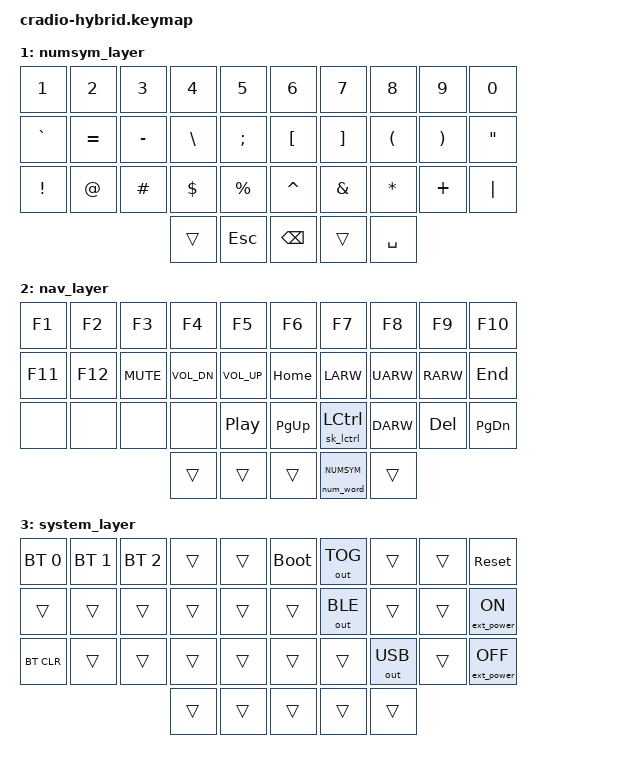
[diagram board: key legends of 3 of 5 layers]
// Copyright (c) 2022 The ZMK Contributors
// SPDX-License-Identifier: MIT
//
// OPTION 4: HYBRID PROGRESSIVE APPROACH
// - Dual-mode layer access (both hold AND toggle available)
// - Gradual transition features with fallback options
// - Selective HRM with optional full HRM mode
// - Experimental features for power users
// - Safe experimentation without losing productivity

#include <behaviors/num_word.dtsi>
#include <behaviors.dtsi>
#include <dt-bindings/zmk/keys.h>
#include <dt-bindings/zmk/bt.h>
#include <dt-bindings/zmk/outputs.h>
#include <dt-bindings/zmk/ext_power.h>

// ---------- Layer indexes ----------
#define BASE     0 
#define NUMSYM   1
#define NAV      2
#define SYSTEM   3
#define ALT_BASE 4  // Alternative base layer with different HRM

// ---------- Full Home-row Mods (original style) ----------
#define HRML_FULL(k1,k2,k3,k4) &ht LSHFT k1  &ht LALT k2   &ht LCTRL k3   &ht LGUI k4
#define HRMR_FULL(k1,k2,k3,k4) &ht RGUI k1   &ht RCTRL k2  &ht RALT k3    &ht RSHFT k4

// ---------- Selective Home-row Mods (experimental) ----------
#define HRML_LITE(k1,k2,k3,k4) &kp k1  &ht_slow LALT k2   &kp k3   &ht_slow LGUI k4
#define HRMR_LITE(k1,k2,k3,k4) &ht_slow RGUI k1   &kp k2  &ht_slow RALT k3    &kp k4

/ {
    behaviors {
        // Original hold-tap for familiar feel
        ht: hold_tap {
            compatible = "zmk,behavior-hold-tap";
            #binding-cells = <2>;
            flavor = "tap-preferred";
            tapping-term-ms = <200>;
            quick-tap-ms = <120>;
            require-prior-idle-ms = <100>;
            bindings = <&kp>, <&kp>;
        };

        // Slower hold-tap for selective HRM
        ht_slow: hold_tap_slow {
            compatible = "zmk,behavior-hold-tap";
            #binding-cells = <2>;
            flavor = "tap-preferred";
            tapping-term-ms = <280>;
            quick-tap-ms = <100>;
            require-prior-idle-ms = <150>;
            bindings = <&kp>, <&kp>;
        };

        // Dual-mode layer access - hold for momentary, tap for toggle
        dual_layer: dual_layer_access {
            compatible = "zmk,behavior-tap-dance";
            #binding-cells = <1>;
            tapping-term-ms = <200>;
            bindings = <&lt_hold>, <&to>;
        };

        // Hold for momentary layer
        lt_hold: layer_tap_hold {
            compatible = "zmk,behavior-hold-tap";
            #binding-cells = <2>;
            flavor = "tap-preferred";
            tapping-term-ms = <200>;
            quick-tap-ms = <120>;
            require-prior-idle-ms = <100>;
            bindings = <&mo>, <&kp>;
        };

        // Sticky modifiers
        sk_lshft: sticky_shift {
            compatible = "zmk,behavior-sticky-key";
            #binding-cells = <1>;
            bindings = <&kp>;
            release-after-ms = <1000>;
            quick-release;
        };

        sk_lctrl: sticky_ctrl {
            compatible = "zmk,behavior-sticky-key";
            #binding-cells = <1>;
            bindings = <&kp>;
            release-after-ms = <1000>;
            quick-release;
        };

        // Experimental multi-function thumb
        mt_experimental: mod_tap_experimental {
            compatible = "zmk,behavior-tap-dance";
            #binding-cells = <0>;
            tapping-term-ms = <200>;
            bindings = <&kp SPACE>, <&sk_lshft LSHFT>, <&to ALT_BASE>;
        };
    };

    // ---------- Combos for advanced functionality ----------
    combos {
        compatible = "zmk,combos";
        
        // Panic mode - always available
        combo_panic {
            timeout-ms = <50>;
            key-positions = <30 33>;
            bindings = <&to BASE>;
            layers = <BASE NUMSYM NAV SYSTEM ALT_BASE>;
        };

        // Essential shortcuts
        combo_enter {
            timeout-ms = <40>;
            key-positions = <17 18 19>; // J K L
            bindings = <&kp ENTER>;
            layers = <BASE ALT_BASE>;
        };

        combo_hyphen {
            timeout-ms = <40>;
            key-positions = <22 23>; // C V
            bindings = <&kp MINUS>;
            layers = <BASE ALT_BASE>;
        };

        combo_tab {
            timeout-ms = <40>;
            key-positions = <12 13>; // D F
            bindings = <&kp TAB>;
            layers = <BASE ALT_BASE>;
        };

        // Quick layer switches
        combo_toggle_nav {
            timeout-ms = <50>;
            key-positions = <14 15>; // T G
            bindings = <&tog NAV>;
            layers = <BASE>;
        };

        combo_toggle_numsym {
            timeout-ms = <50>;
            key-positions = <15 16>; // G H
            bindings = <&tog NUMSYM>;
            layers = <BASE>;
        };

        // Switch between HRM modes
        combo_switch_hrm {
            timeout-ms = <100>;
            key-positions = <0 1 8 9>; // Q W O P
            bindings = <&tog ALT_BASE>;
            layers = <BASE ALT_BASE>;
        };
    };

    // ---------- Conditional tri-layer ----------
    conditional_layers {
        compatible = "zmk,conditional-layers";
        system_layer {
            if-layers = <NAV NUMSYM>;
            then-layer = <SYSTEM>;
        };
    };

    keymap {
        compatible = "zmk,keymap";
        
        // Original style base layer with full HRM
        base_layer {
            bindings = <
        //╭──────────┬──────────┬──────────┬──────────┬──────────╮   ╭──────────┬──────────┬──────────┬──────────┬──────────╮
        //│  Q       │  W       │  E       │  R       │  T       │   │  Y       │  U       │  I       │  O       │  P       │
             &kp Q      &kp W      &kp E      &kp R      &kp T          &kp Y      &kp U      &kp I      &kp O      &kp P
        //├──────────┼──────────┼──────────┼──────────┼──────────┤   ├──────────┼──────────┼──────────┼──────────┼──────────┤
        //│  A       │  S       │  D       │  F       │  G       │   │  H       │  J       │  K       │  L       │ ' "      │
             HRML_FULL(A, S,       D,         F)         &kp G          &kp H      HRMR_FULL(J, K,       L,        SQT)
        //├──────────┼──────────┼──────────┼──────────┼──────────┤   ├──────────┼──────────┼──────────┼──────────┼──────────┤
        //│  Z       │  X       │  C       │  V       │  B       │   │  N       │  M       │ , <      │ . >      │ / ?      │
            &kp Z      &kp X      &kp C      &kp V      &kp B          &kp N      &kp M      &kp COMMA  &kp DOT    &kp FSLH
        //╰──────────┴──────────┴──────────┼──────────┼──────────┤   ├──────────┼──────────┼──────────┴──────────┴──────────╯
                                 &dual_layer NAV &lt_hold NAV TAB    &kp ENTER  &lt_hold NUMSYM BSPC &mt_experimental
        //                                 ╰──────────┴──────────╯   ╰──────────┴──────────╯
            >;
        };

        numsym_layer {
            bindings = <
        //╭──────────┬──────────┬──────────┬──────────┬──────────╮   ╭──────────┬──────────┬──────────┬──────────┬──────────╮
        //│ 1        │ 2        │ 3        │ 4        │ 5        │   │ 6        │ 7        │ 8        │ 9        │  0       │
            &kp N1     &kp N2     &kp N3     &kp N4     &kp N5         &kp N6     &kp N7     &kp N8     &kp N9     &kp N0
        //├──────────┼──────────┼──────────┼──────────┼──────────┤   ├──────────┼──────────┼──────────┼──────────┼──────────┤
        //│ ` ~      │ = +      │ - _      │  \ |     │  ; :     │   │ [ {      │ ] }      │ ( )      │ ) }      │  " '     │
            &kp GRAVE  &kp EQUAL  &kp MINUS  &kp BSLH   &kp SEMI       &kp LBKT   &kp RBKT   &kp LPAR   &kp RPAR   &kp DQT
        //├──────────┼──────────┼──────────┼──────────┼──────────┤   ├──────────┼──────────┼──────────┼──────────┼──────────┤
        //│ !        │ @        │ #        │ $        │ %        │   │ ^        │ &        │ *        │ +        │ |        │
            &kp EXCL   &kp AT     &kp HASH   &kp DLLR   &kp PRCNT      &kp CARET  &kp AMPS   &kp STAR   &kp PLUS   &kp PIPE
        //╰──────────┴──────────┴──────────┼──────────┼──────────┤   ├──────────┼──────────┼──────────┴──────────┴──────────╯
                                             &trans     &kp ESC        &kp BSPC   &trans     &kp SPACE
        //                                 ╰──────────┴──────────╯   ╰──────────┴──────────╯
            >;
        };

        nav_layer {
            bindings = <
        //╭──────────┬──────────┬──────────┬──────────┬──────────╮   ╭──────────┬──────────┬──────────┬──────────┬──────────╮
        //│  F1      │  F2      │  F3      │  F4      │ F5       │   │  F6      │  F7      │  F8      │  F9      │  F10     │
             &kp F1     &kp F2     &kp F3     &kp F4    &kp F5          &kp F6     &kp F7     &kp F8     &kp F9     &kp F10
        //├──────────┼──────────┼──────────┼──────────┼──────────┤   ├──────────┼──────────┼──────────┼──────────┼──────────┤
        //│  F11     │  F12     │  Mute    │  VOL DN  │ VOL UP   │   │  HOME    │  LEFT    │  UP      │ RIGHT    │   END    │
             &kp F11    &kp F12   &kp K_MUTE &kp C_VOL_DN &kp C_VOL_UP   &kp HOME   &kp LARW   &kp UARW   &kp RARW   &kp END
        //├──────────┼──────────┼──────────┼──────────┼──────────┤   ├──────────┼──────────┼──────────┼──────────┼──────────┤
        //│          │          │          │          │ PLAY     │   │ PAGE_UP  │ CTRL     │ DOWN     │   DEL    │ PAGE_DN  │
             &none     &none       &none      &none     &kp C_PP        &kp PG_UP  &sk_lctrl LCTRL &kp DARW &kp DEL &kp PG_DN
        //╰──────────┴──────────┴──────────┼──────────┼──────────┤   ├──────────┼──────────┼──────────┴──────────┴──────────╯
                                                 &trans     &trans         &trans     &num_word NUMSYM &trans
        //                                 ╰──────────┴──────────╯   ╰──────────┴──────────╯
            >;
        };

        system_layer {
            bindings = <
        //╭──────────┬──────────┬──────────┬──────────┬──────────╮   ╭──────────┬──────────┬──────────┬──────────┬──────────╮
        //│ PROFILE 0│ PROFILE 1│PROFILE 2 │          │		 │   │BOOTLOADER│          │          │          │  RESET   │
        &bt BT_SEL 0  &bt BT_SEL 1 &bt BT_SEL 2 &trans  	&trans        &bootloader &out OUT_TOG &trans      &trans   &sys_reset
        //├──────────┼──────────┼──────────┼──────────┼──────────┤   ├──────────┼──────────┼──────────┼──────────┼──────────┤
        //│          │          │          │          │          │   │          │          │          │          │EP ON     │
           &trans      &trans     &trans     &trans    &trans          &trans &out OUT_BLE     &trans     &trans  &ext_power EP_ON
        //├──────────┼──────────┼──────────┼──────────┼──────────┤   ├──────────┼──────────┼──────────┼──────────┼──────────┤
        //│ CLEAR BT │          │          │          │	         │   │          │          │          │          │EP OFF    │
           &bt BT_CLR  &trans     &trans    &trans	&trans          &trans     &trans   &out OUT_USB  &trans  &ext_power EP_OFF
        //╰──────────┴──────────┴──────────┼──────────┼──────────┤   ├──────────┼──────────┼──────────┴──────────┴──────────╯
                                          &trans     &trans         &trans     &trans     &trans
        //                                 ╰──────────┴──────────╯   ╰──────────┴──────────╯
            >;
        };

        // Alternative base layer with selective HRM
        alt_base_layer {
            bindings = <
        //╭──────────┬──────────┬──────────┬──────────┬──────────╮   ╭──────────┬──────────┬──────────┬──────────┬──────────╮
        //│  Q       │  W       │  E       │  R       │  T       │   │  Y       │  U       │  I       │  O       │  P       │
             &kp Q      &kp W      &kp E      &kp R      &kp T          &kp Y      &kp U      &kp I      &kp O      &kp P
        //├──────────┼──────────┼──────────┼──────────┼──────────┤   ├──────────┼──────────┼──────────┼──────────┼──────────┤
        //│  A       │  S       │  D       │  F       │  G       │   │  H       │  J       │  K       │  L       │ ' "      │
             HRML_LITE(A, S,       D,         F)         &kp G          &kp H      HRMR_LITE(J, K,       L,        SQT)
        //├──────────┼──────────┼──────────┼──────────┼──────────┤   ├──────────┼──────────┼──────────┼──────────┼──────────┤
        //│  Z       │  X       │  C       │  V       │  B       │   │  N       │  M       │ , <      │ . >      │ / ?      │
            &kp Z      &kp X      &kp C      &kp V      &kp B          &kp N      &kp M      &kp COMMA  &kp DOT    &kp FSLH
        //╰──────────┴──────────┴──────────┼──────────┼──────────┤   ├──────────┼──────────┼──────────┴──────────┴──────────╯
                               &sk_lshft LSHFT  &lt_hold NAV TAB    &kp ENTER  &sk_lctrl LCTRL &lt_hold NUMSYM SPACE
        //                                 ╰──────────┴──────────╯   ╰──────────┴──────────╯
            >;
        };
    };
};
